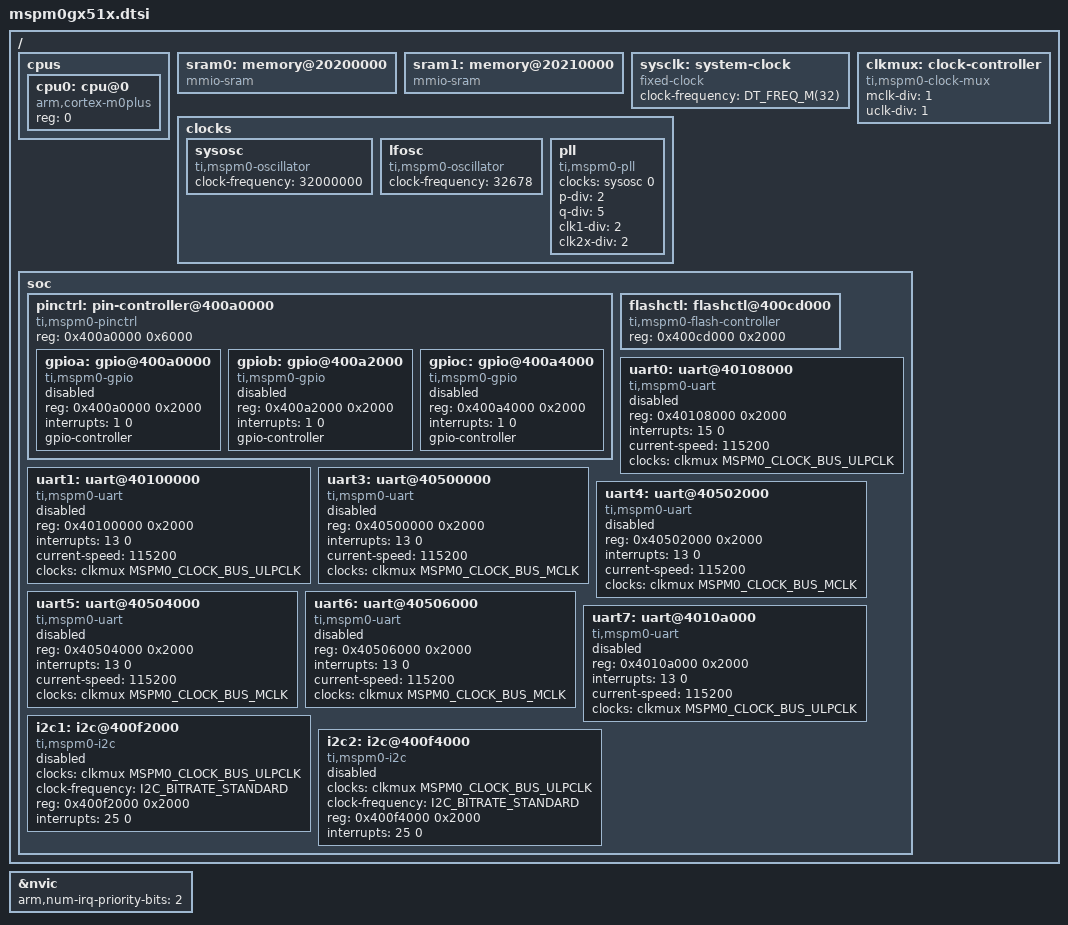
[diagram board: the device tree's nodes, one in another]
/* SPDX-License-Identifier: Apache-2.0 */

#include <arm/armv6-m.dtsi>
#include <zephyr/dt-bindings/gpio/gpio.h>
#include <zephyr/dt-bindings/i2c/i2c.h>
#include <zephyr/dt-bindings/clock/mspm0_clock.h>
#include <freq.h>

/ {

	cpus {
		#address-cells = <1>;
		#size-cells = <0>;

		cpu0: cpu@0 {
			compatible = "arm,cortex-m0plus";
			reg = <0>;
		};
	};

	sram0: memory@20200000 {
		compatible = "mmio-sram";
	};

	sram1: memory@20210000 {
		compatible = "mmio-sram";
	};

	sysclk: system-clock {
		compatible = "fixed-clock";
		clock-frequency = <DT_FREQ_M(32)>;
		#clock-cells = <0>;
	};

	clkmux: clock-controller {
		compatible = "ti,mspm0-clock-mux";
		mclk-div = <1>;
		uclk-div = <1>;
		#clock-cells = <1>;
	};

	clocks: clocks {
		sysosc: sysosc {
			compatible = "ti,mspm0-oscillator";
			clock-frequency = <32000000>;
			#clock-cells = <1>;
		};

		lfosc: lfosc {
			compatible = "ti,mspm0-oscillator";
			clock-frequency = <32678>;
			#clock-cells = <1>;
		};

		pll: pll {
			compatible = "ti,mspm0-pll";
			clocks = <&sysosc 0>;
			p-div = <2>;
			q-div = <5>;
			clk1-div = <2>;
			clk2x-div = <2>;
			#clock-cells = <0>;
			status = "okay";
		};
	};

	soc {
		pinctrl: pin-controller@400a0000{
			compatible = "ti,mspm0-pinctrl";
			#address-cells = <1>;
			#size-cells = <1>;
			reg = <0x400a0000 0x6000>;

			gpioa: gpio@400a0000 {
				compatible = "ti,mspm0-gpio";
				reg = <0x400a0000 0x2000>;
				interrupts = <1 0>;
				status = "disabled";
				gpio-controller;
				#gpio-cells = <2>;
			};

			gpiob: gpio@400a2000 {
				compatible = "ti,mspm0-gpio";
				reg = <0x400a2000 0x2000>;
				interrupts = <1 0>;
				status = "disabled";
				gpio-controller;
				#gpio-cells = <2>;
			};

			gpioc: gpio@400a4000 {
				compatible = "ti,mspm0-gpio";
				reg = <0x400a4000 0x2000>;
				interrupts = <1 0>;
				status = "disabled";
				gpio-controller;
				#gpio-cells = <2>;
			};
		};

		flashctl: flashctl@400cd000{
			compatible = "ti,mspm0-flash-controller";
			reg = <0x400cd000 0x2000>;
			status = "okay";

			#address-cells = <1>;
			#size-cells = <1>;
		};

		uart0: uart@40108000 {
			compatible = "ti,mspm0-uart";
			reg = <0x40108000 0x2000>;
			interrupts = <15 0>;
			current-speed = <115200>;
			clocks = <&clkmux MSPM0_CLOCK_BUS_ULPCLK>;
			status = "disabled";
		};

		uart1: uart@40100000 {
			compatible = "ti,mspm0-uart";
			reg = <0x40100000 0x2000>;
			interrupts = <13 0>;
			current-speed = <115200>;
			clocks = <&clkmux MSPM0_CLOCK_BUS_ULPCLK>;
			status = "disabled";
		};
		
		uart3: uart@40500000 {
			compatible = "ti,mspm0-uart";
			reg = <0x40500000 0x2000>;
			interrupts = <13 0>;
			current-speed = <115200>;
			clocks = <&clkmux MSPM0_CLOCK_BUS_MCLK>;
			status = "disabled";
		};
		
		uart4: uart@40502000 {
			compatible = "ti,mspm0-uart";
			reg = <0x40502000 0x2000>;
			interrupts = <13 0>;
			current-speed = <115200>;
			clocks = <&clkmux MSPM0_CLOCK_BUS_MCLK>;
			status = "disabled";
		};

		uart5: uart@40504000 {
			compatible = "ti,mspm0-uart";
			reg = <0x40504000 0x2000>;
			interrupts = <13 0>;
			current-speed = <115200>;
			clocks = <&clkmux MSPM0_CLOCK_BUS_MCLK>;
			status = "disabled";
		};

		uart6: uart@40506000 {
			compatible = "ti,mspm0-uart";
			reg = <0x40506000 0x2000>;
			interrupts = <13 0>;
			current-speed = <115200>;
			clocks = <&clkmux MSPM0_CLOCK_BUS_MCLK>;
			status = "disabled";
		};

		uart7: uart@4010a000 {
			compatible = "ti,mspm0-uart";
			reg = <0x4010a000 0x2000>;
			interrupts = <13 0>;
			current-speed = <115200>;
			clocks = <&clkmux MSPM0_CLOCK_BUS_ULPCLK>;
			status = "disabled";
		};

		i2c1: i2c@400f2000 {
			compatible = "ti,mspm0-i2c";
			clocks = <&clkmux MSPM0_CLOCK_BUS_ULPCLK>;
			clock-frequency = <I2C_BITRATE_STANDARD>;
			#address-cells = <1>;
			#size-cells = <0>;
			reg = <0x400f2000 0x2000>;
			interrupts = <25 0>;
			status = "disabled";
		};
		
		i2c2: i2c@400f4000 {
			compatible = "ti,mspm0-i2c";
			clocks = <&clkmux MSPM0_CLOCK_BUS_ULPCLK>;
			clock-frequency = <I2C_BITRATE_STANDARD>;
			#address-cells = <1>;
			#size-cells = <0>;
			reg = <0x400f4000 0x2000>;
			interrupts = <25 0>;
			status = "disabled";
		};
	};
};

&nvic {
	arm,num-irq-priority-bits = <2>;
};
